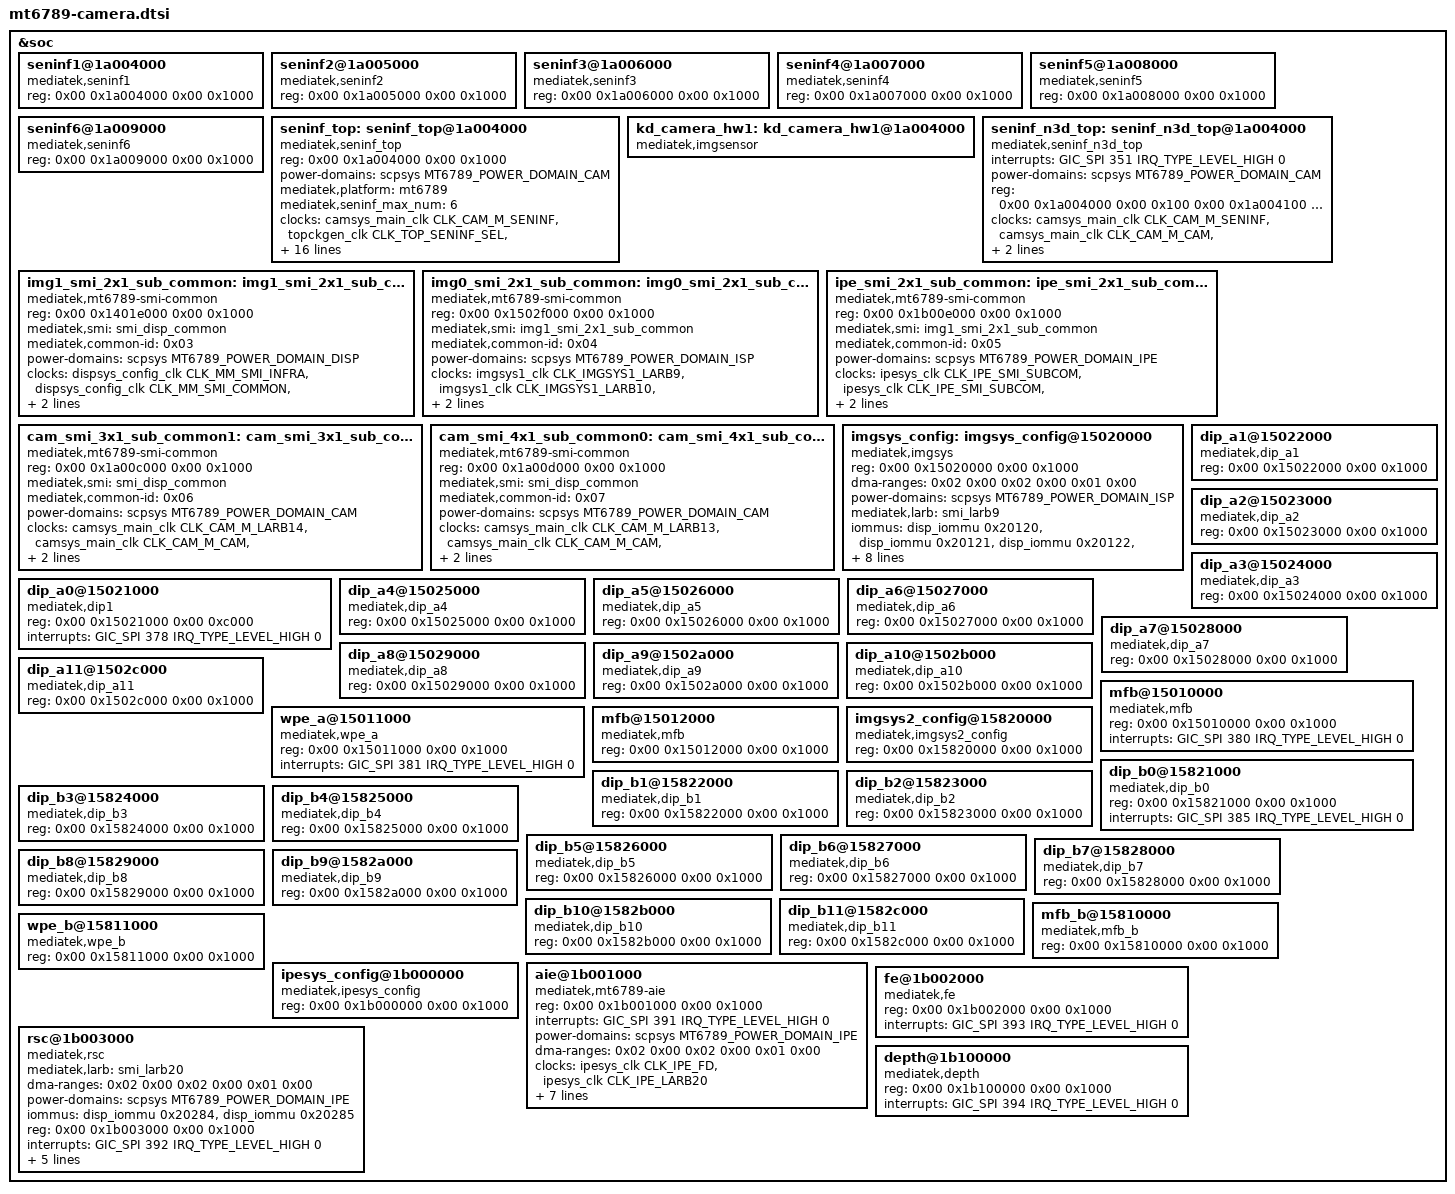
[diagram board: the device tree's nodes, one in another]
// SPDX-License-Identifier: (GPL-2.0 OR MIT)
/* MT6789 camera blocks - split out of the soc node by tools/scripts/dts-socsplit.py */

&soc {
	seninf1@1a004000 {
		compatible = "mediatek,seninf1";
		reg = <0x00 0x1a004000 0x00 0x1000>;
	};

	seninf2@1a005000 {
		compatible = "mediatek,seninf2";
		reg = <0x00 0x1a005000 0x00 0x1000>;
	};

	seninf3@1a006000 {
		compatible = "mediatek,seninf3";
		reg = <0x00 0x1a006000 0x00 0x1000>;
	};

	seninf4@1a007000 {
		compatible = "mediatek,seninf4";
		reg = <0x00 0x1a007000 0x00 0x1000>;
	};

	seninf5@1a008000 {
		compatible = "mediatek,seninf5";
		reg = <0x00 0x1a008000 0x00 0x1000>;
	};

	seninf6@1a009000 {
		compatible = "mediatek,seninf6";
		reg = <0x00 0x1a009000 0x00 0x1000>;
	};

	seninf_top: seninf_top@1a004000 {
		compatible = "mediatek,seninf_top";
		reg = <0x00 0x1a004000 0x00 0x1000>;
		power-domains = <&scpsys MT6789_POWER_DOMAIN_CAM>;
		mediatek,platform = "mt6789";
		mediatek,seninf_max_num = "6";
		clocks = <&camsys_main_clk CLK_CAM_M_SENINF &topckgen_clk CLK_TOP_SENINF_SEL &topckgen_clk CLK_TOP_SENINF1_SEL &topckgen_clk CLK_TOP_SENINF2_SEL &topckgen_clk CLK_TOP_SENINF3_SEL &topckgen_clk CLK_TOP_CAMTG_SEL &topckgen_clk CLK_TOP_CAMTG2_SEL &topckgen_clk CLK_TOP_CAMTG3_SEL &topckgen_clk CLK_TOP_CAMTG4_SEL &topckgen_clk CLK_TOP_TCK_26M_MX9 &topckgen_clk CLK_TOP_UNIVPLL_192M_D8 &topckgen_clk CLK_TOP_UNIVPLL_D6_D8 &topckgen_clk CLK_TOP_UNIVPLL_192M_D4 &topckgen_clk CLK_TOP_F26M_CK_D2 &topckgen_clk CLK_TOP_UNIVPLL_192M_D16 &topckgen_clk CLK_TOP_UNIVPLL_192M_D32>;
		clock-names = "CAMSYS_SENINF_CGPDN", "TOP_MUX_SENINF", "TOP_MUX_SENINF1", "TOP_MUX_SENINF2", "TOP_MUX_SENINF3", "TOP_MUX_CAMTG", "TOP_MUX_CAMTG2", "TOP_MUX_CAMTG3", "TOP_MUX_CAMTG4", "TOP_CLK26M", "TOP_UNIVP_192M_D8", "TOP_UNIVPLL_D6_D8", "TOP_UNIVP_192M_D4", "TOP_F26M_CK_D2", "TOP_UNIVP_192M_D16", "TOP_UNIVP_192M_D32";
		operating-points-v2 = <&opp_table_cam>;
		dvfsrc-vcore-supply = <&dvfsrc_vcore>;
	};

	kd_camera_hw1: kd_camera_hw1@1a004000 {
		compatible = "mediatek,imgsensor";
	};

	seninf_n3d_top: seninf_n3d_top@1a004000 {
		compatible = "mediatek,seninf_n3d_top";
		interrupts = <GIC_SPI 351 IRQ_TYPE_LEVEL_HIGH 0>;
		power-domains = <&scpsys MT6789_POWER_DOMAIN_CAM>;
		reg = <0x00 0x1a004000 0x00 0x100 0x00 0x1a004100 0x00 0x100 0x00 0x1a004200 0x00 0x100>;
		reg-names = "seninf_top", "seninf_n3d_a", "seninf_n3d_b";
		clocks = <&camsys_main_clk CLK_CAM_M_SENINF &camsys_main_clk CLK_CAM_M_CAM &camsys_main_clk CLK_CAM_M_CAMTG &topckgen_clk CLK_TOP_CAMTM_SEL>;
		clock-names = "CAMSYS_SENINF_CGPDN", "CAMSYS_CAM_CGPDN", "CAMSYS_CAMTG_CGPDN", "CAMSYS_CAMTM_SEL";
	};

	img1_smi_2x1_sub_common: img1_smi_2x1_sub_comm@1401e000 {
		compatible = "mediatek,mt6789-smi-common", "syscon", "mediatek,smi-common", "mediatek,smi-sub-common";
		reg = <0x00 0x1401e000 0x00 0x1000>;
		mediatek,smi = <&smi_disp_common>;
		mediatek,common-id = <0x03>;
		power-domains = <&scpsys MT6789_POWER_DOMAIN_DISP>;
		clocks = <&dispsys_config_clk CLK_MM_SMI_INFRA &dispsys_config_clk CLK_MM_SMI_COMMON &dispsys_config_clk CLK_MM_SMI_GALS &dispsys_config_clk CLK_MM_SMI_IOMMU>;
		clock-names = "apb", "smi", "gals0", "gals1";
	};

	img0_smi_2x1_sub_common: img0_smi_2x1_sub_comm@1502f000 {
		compatible = "mediatek,mt6789-smi-common", "syscon", "mediatek,smi-common", "mediatek,smi-sub-common";
		reg = <0x00 0x1502f000 0x00 0x1000>;
		mediatek,smi = <&img1_smi_2x1_sub_common>;
		mediatek,common-id = <0x04>;
		power-domains = <&scpsys MT6789_POWER_DOMAIN_ISP>;
		clocks = <&imgsys1_clk CLK_IMGSYS1_LARB9 &imgsys1_clk CLK_IMGSYS1_LARB10 &imgsys1_clk CLK_IMGSYS1_DIP &imgsys1_clk CLK_IMGSYS1_GALS>;
		clock-names = "apb", "smi", "gals0", "gals1";
	};

	ipe_smi_2x1_sub_common: ipe_smi_2x1_sub_comm@1b00e000 {
		compatible = "mediatek,mt6789-smi-common", "syscon", "mediatek,smi-common", "mediatek,smi-sub-common";
		reg = <0x00 0x1b00e000 0x00 0x1000>;
		mediatek,smi = <&img1_smi_2x1_sub_common>;
		mediatek,common-id = <0x05>;
		power-domains = <&scpsys MT6789_POWER_DOMAIN_IPE>;
		clocks = <&ipesys_clk CLK_IPE_SMI_SUBCOM &ipesys_clk CLK_IPE_SMI_SUBCOM &ipesys_clk CLK_IPE_SMI_SUBCOM &ipesys_clk CLK_IPE_SMI_SUBCOM>;
		clock-names = "apb", "smi", "gals0", "gals1";
	};

	cam_smi_3x1_sub_common1: cam_smi_3x1_sub_comm1@1a00c000 {
		compatible = "mediatek,mt6789-smi-common", "syscon", "mediatek,smi-common", "mediatek,smi-sub-common";
		reg = <0x00 0x1a00c000 0x00 0x1000>;
		mediatek,smi = <&smi_disp_common>;
		mediatek,common-id = <0x06>;
		power-domains = <&scpsys MT6789_POWER_DOMAIN_CAM>;
		clocks = <&camsys_main_clk CLK_CAM_M_LARB14 &camsys_main_clk CLK_CAM_M_CAM &camsys_main_clk CLK_CAM_M_LARB14 &camsys_main_clk CLK_CAM_M_CAM>;
		clock-names = "apb", "smi", "gals0", "gals1";
	};

	cam_smi_4x1_sub_common0: cam_smi_4x1_sub_comm0@1a00d000 {
		compatible = "mediatek,mt6789-smi-common", "syscon", "mediatek,smi-common", "mediatek,smi-sub-common";
		reg = <0x00 0x1a00d000 0x00 0x1000>;
		mediatek,smi = <&smi_disp_common>;
		mediatek,common-id = <0x07>;
		power-domains = <&scpsys MT6789_POWER_DOMAIN_CAM>;
		clocks = <&camsys_main_clk CLK_CAM_M_LARB13 &camsys_main_clk CLK_CAM_M_CAM &camsys_main_clk CLK_CAM_M_LARB13 &camsys_main_clk CLK_CAM_M_CAM>;
		clock-names = "apb", "smi", "gals0", "gals1";
	};

	imgsys_config: imgsys_config@15020000 {
		#address-cells = <2>;
		#size-cells = <2>;
		compatible = "mediatek,imgsys", "syscon";
		reg = <0x00 0x15020000 0x00 0x1000>;
		dma-ranges = <0x02 0x00 0x02 0x00 0x01 0x00>;
		power-domains = <&scpsys MT6789_POWER_DOMAIN_ISP>;
		mediatek,larb = <&smi_larb9>;
		iommus = <&disp_iommu 0x20120 &disp_iommu 0x20121 &disp_iommu 0x20122 &disp_iommu 0x20123 &disp_iommu 0x20124 &disp_iommu 0x20125 &disp_iommu 0x20126 &disp_iommu 0x20127 &disp_iommu 0x20128 &disp_iommu 0x20129 &disp_iommu 0x2012a &disp_iommu 0x2012b &disp_iommu 0x2012c &disp_iommu 0x2012d &disp_iommu 0x2012e>;
		clocks = <&imgsys1_clk CLK_IMGSYS1_LARB9 &imgsys1_clk CLK_IMGSYS1_DIP>;
		clock-names = "DIP_CG_IMG_LARB9", "DIP_CG_IMG_DIP";
	};

	dip_a0@15021000 {
		compatible = "mediatek,dip1";
		reg = <0x00 0x15021000 0x00 0xc000>;
		interrupts = <GIC_SPI 378 IRQ_TYPE_LEVEL_HIGH 0>;
	};

	dip_a1@15022000 {
		compatible = "mediatek,dip_a1";
		reg = <0x00 0x15022000 0x00 0x1000>;
	};

	dip_a2@15023000 {
		compatible = "mediatek,dip_a2";
		reg = <0x00 0x15023000 0x00 0x1000>;
	};

	dip_a3@15024000 {
		compatible = "mediatek,dip_a3";
		reg = <0x00 0x15024000 0x00 0x1000>;
	};

	dip_a4@15025000 {
		compatible = "mediatek,dip_a4";
		reg = <0x00 0x15025000 0x00 0x1000>;
	};

	dip_a5@15026000 {
		compatible = "mediatek,dip_a5";
		reg = <0x00 0x15026000 0x00 0x1000>;
	};

	dip_a6@15027000 {
		compatible = "mediatek,dip_a6";
		reg = <0x00 0x15027000 0x00 0x1000>;
	};

	dip_a7@15028000 {
		compatible = "mediatek,dip_a7";
		reg = <0x00 0x15028000 0x00 0x1000>;
	};

	dip_a8@15029000 {
		compatible = "mediatek,dip_a8";
		reg = <0x00 0x15029000 0x00 0x1000>;
	};

	dip_a9@1502a000 {
		compatible = "mediatek,dip_a9";
		reg = <0x00 0x1502a000 0x00 0x1000>;
	};

	dip_a10@1502b000 {
		compatible = "mediatek,dip_a10";
		reg = <0x00 0x1502b000 0x00 0x1000>;
	};

	dip_a11@1502c000 {
		compatible = "mediatek,dip_a11";
		reg = <0x00 0x1502c000 0x00 0x1000>;
	};

	mfb@15010000 {
		compatible = "mediatek,mfb";
		reg = <0x00 0x15010000 0x00 0x1000>;
		interrupts = <GIC_SPI 380 IRQ_TYPE_LEVEL_HIGH 0>;
	};

	wpe_a@15011000 {
		compatible = "mediatek,wpe_a";
		reg = <0x00 0x15011000 0x00 0x1000>;
		interrupts = <GIC_SPI 381 IRQ_TYPE_LEVEL_HIGH 0>;
	};

	mfb@15012000 {
		compatible = "mediatek,mfb";
		reg = <0x00 0x15012000 0x00 0x1000>;
	};

	imgsys2_config@15820000 {
		compatible = "mediatek,imgsys2_config";
		reg = <0x00 0x15820000 0x00 0x1000>;
	};

	dip_b0@15821000 {
		compatible = "mediatek,dip_b0";
		reg = <0x00 0x15821000 0x00 0x1000>;
		interrupts = <GIC_SPI 385 IRQ_TYPE_LEVEL_HIGH 0>;
	};

	dip_b1@15822000 {
		compatible = "mediatek,dip_b1";
		reg = <0x00 0x15822000 0x00 0x1000>;
	};

	dip_b2@15823000 {
		compatible = "mediatek,dip_b2";
		reg = <0x00 0x15823000 0x00 0x1000>;
	};

	dip_b3@15824000 {
		compatible = "mediatek,dip_b3";
		reg = <0x00 0x15824000 0x00 0x1000>;
	};

	dip_b4@15825000 {
		compatible = "mediatek,dip_b4";
		reg = <0x00 0x15825000 0x00 0x1000>;
	};

	dip_b5@15826000 {
		compatible = "mediatek,dip_b5";
		reg = <0x00 0x15826000 0x00 0x1000>;
	};

	dip_b6@15827000 {
		compatible = "mediatek,dip_b6";
		reg = <0x00 0x15827000 0x00 0x1000>;
	};

	dip_b7@15828000 {
		compatible = "mediatek,dip_b7";
		reg = <0x00 0x15828000 0x00 0x1000>;
	};

	dip_b8@15829000 {
		compatible = "mediatek,dip_b8";
		reg = <0x00 0x15829000 0x00 0x1000>;
	};

	dip_b9@1582a000 {
		compatible = "mediatek,dip_b9";
		reg = <0x00 0x1582a000 0x00 0x1000>;
	};

	dip_b10@1582b000 {
		compatible = "mediatek,dip_b10";
		reg = <0x00 0x1582b000 0x00 0x1000>;
	};

	dip_b11@1582c000 {
		compatible = "mediatek,dip_b11";
		reg = <0x00 0x1582c000 0x00 0x1000>;
	};

	mfb_b@15810000 {
		compatible = "mediatek,mfb_b";
		reg = <0x00 0x15810000 0x00 0x1000>;
	};

	wpe_b@15811000 {
		compatible = "mediatek,wpe_b";
		reg = <0x00 0x15811000 0x00 0x1000>;
	};

	ipesys_config@1b000000 {
		compatible = "mediatek,ipesys_config";
		reg = <0x00 0x1b000000 0x00 0x1000>;
	};

	aie@1b001000 {
		#address-cells = <2>;
		#size-cells = <2>;
		compatible = "mediatek,mt6789-aie", "mediatek,aie-hw2.0";
		reg = <0x00 0x1b001000 0x00 0x1000>;
		interrupts = <GIC_SPI 391 IRQ_TYPE_LEVEL_HIGH 0>;
		power-domains = <&scpsys MT6789_POWER_DOMAIN_IPE>;
		dma-ranges = <0x02 0x00 0x02 0x00 0x01 0x00>;
		clocks = <&ipesys_clk CLK_IPE_FD &ipesys_clk CLK_IPE_LARB20>;
		clock-names = "aie", "FDVT_CLK_IPE_LARB20";
		mboxes = <&gce 0x14 0x00 0x01 &gce_sec 0xb 0x00 0x01>;
		iommus = <&disp_iommu 0x20280 &disp_iommu 0x20281 &disp_iommu 0x20282 &disp_iommu 0x20283>;
		fdvt_frame_done = <0xb1>;
		mediatek,larb = <&smi_larb20>;
	};

	fe@1b002000 {
		compatible = "mediatek,fe";
		reg = <0x00 0x1b002000 0x00 0x1000>;
		interrupts = <GIC_SPI 393 IRQ_TYPE_LEVEL_HIGH 0>;
	};

	rsc@1b003000 {
		#address-cells = <2>;
		#size-cells = <2>;
		compatible = "mediatek,rsc";
		mediatek,larb = <&smi_larb20>;
		dma-ranges = <0x02 0x00 0x02 0x00 0x01 0x00>;
		power-domains = <&scpsys MT6789_POWER_DOMAIN_IPE>;
		iommus = <&disp_iommu 0x20284 &disp_iommu 0x20285>;
		reg = <0x00 0x1b003000 0x00 0x1000>;
		interrupts = <GIC_SPI 392 IRQ_TYPE_LEVEL_HIGH 0>;
		mboxes = <&gce 0x15 0x00 0x01>;
		gce-event-names = "rsc_eof";
		gce-events = <&gce 0xb3>;
		clocks = <&ipesys_clk CLK_IPE_RSC &ipesys_clk CLK_IPE_LARB20>;
		clock-names = "RSC_CLK_IPE_RSC", "RSC_CLK_IPE_LARB20";
	};

	depth@1b100000 {
		compatible = "mediatek,depth";
		reg = <0x00 0x1b100000 0x00 0x1000>;
		interrupts = <GIC_SPI 394 IRQ_TYPE_LEVEL_HIGH 0>;
	};

};
